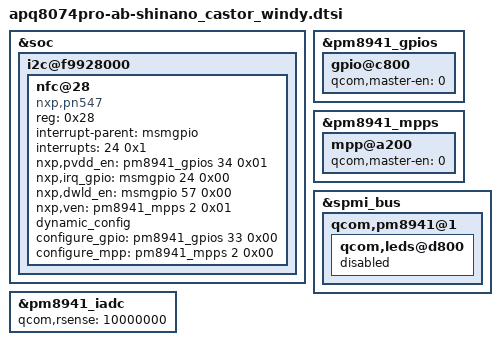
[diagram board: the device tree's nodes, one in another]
/* arch/arm/boot/dts/apq8074pro-ab-shinano_castor_windy.dtsi
 *
 * Copyright (C) 2013 Sony Mobile Communications Inc.
 *
 * Author: Kouhei Fujiya <Kouhei.X.Fujiya@sonymobile.com>
 *
 * This program is free software; you can redistribute it and/or modify
 * it under the terms of the GNU General Public License version 2 and
 * only version 2 as published by the Free Software Foundation.
 *
 * This program is distributed in the hope that it will be useful,
 * but WITHOUT ANY WARRANTY; without even the implied warranty of
 * MERCHANTABILITY or FITNESS FOR A PARTICULAR PURPOSE.  See the
 * GNU General Public License for more details.
 */

&soc {
	/* I2C : BLSP6 */
	i2c@f9928000 {
		nfc@28 {
			compatible = "nxp,pn547";
			reg = <0x28>;
			interrupt-parent = <&msmgpio>;
			interrupts = <24 0x1>;
			nxp,pvdd_en = <&pm8941_gpios 34 0x01>;
			nxp,irq_gpio = <&msmgpio 24 0x00>;
			nxp,dwld_en = <&msmgpio 57 0x00>;
			nxp,ven = <&pm8941_mpps 2 0x01>;
			dynamic_config;
			configure_gpio = <&pm8941_gpios 33 0x00>;
			configure_mpp = <&pm8941_mpps 2 0x00>;
		};
	};
};

&pm8941_gpios {
	/* GPIO_9: NC */
	gpio@c800 {
		qcom,master-en = <0>;		/* Disable */
		status = "ok";
	};
};

&pm8941_mpps {
	/* MPP_3: NC (TXDAC0_VREF) */
	mpp@a200 {
		qcom,master-en = <0>;		/* Disable */
		status = "ok";
	};
};


&spmi_bus {
	qcom,pm8941@1 {
		qcom,leds@d800 {
			status = "disabled";
		};
	};
};

&pm8941_iadc {
	qcom,rsense = <10000000>;
};

